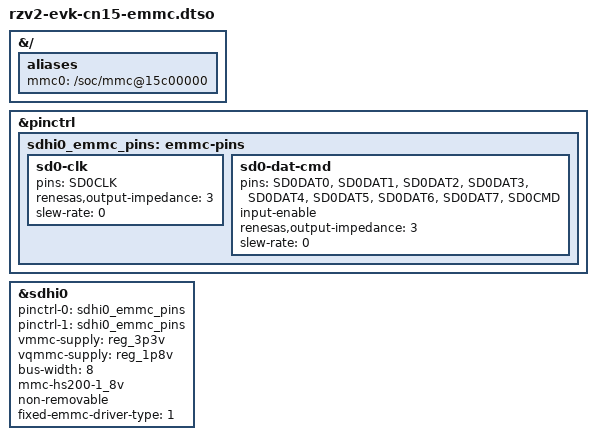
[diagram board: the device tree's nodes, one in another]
// SPDX-License-Identifier: GPL-2.0
/*
 * Shared DT overlay for the eMMC Sub Board (RTK0EF0186B02000BJ), which
 * is connected to the CN15 connector on the RZ/V2H and RZ/V2N EVKs.
 *
 * Copyright (C) 2025 Renesas Electronics Corp.
 */

/dts-v1/;
/plugin/;

#include <dt-bindings/gpio/gpio.h>
#include <dt-bindings/pinctrl/rzg2l-pinctrl.h>

&{/} {
	aliases {
		mmc0 = "/soc/mmc@15c00000";
	};
};

&pinctrl {
	sdhi0_emmc_pins: emmc-pins {
		sd0-clk {
			pins = "SD0CLK";
			renesas,output-impedance = <3>;
			slew-rate = <0>;
		};

		sd0-dat-cmd {
			pins = "SD0DAT0", "SD0DAT1", "SD0DAT2", "SD0DAT3", "SD0DAT4",
			       "SD0DAT5", "SD0DAT6", "SD0DAT7", "SD0CMD";
			input-enable;
			renesas,output-impedance = <3>;
			slew-rate = <0>;
		};
	};
};

&sdhi0 {
	pinctrl-0 = <&sdhi0_emmc_pins>;
	pinctrl-1 = <&sdhi0_emmc_pins>;
	pinctrl-names = "default", "state_uhs";
	vmmc-supply = <&reg_3p3v>;
	vqmmc-supply = <&reg_1p8v>;
	bus-width = <8>;
	mmc-hs200-1_8v;
	non-removable;
	fixed-emmc-driver-type = <1>;
	status = "okay";
};
